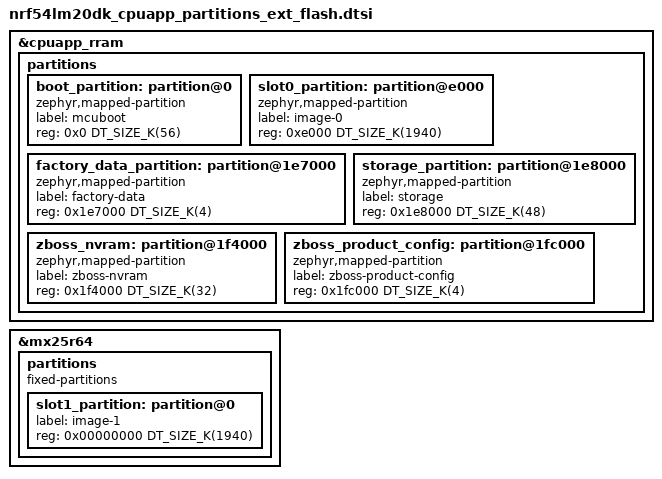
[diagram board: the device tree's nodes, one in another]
/*
 * Copyright (c) 2026 Nordic Semiconductor ASA
 *
 * SPDX-License-Identifier: LicenseRef-Nordic-5-Clause
 */

/delete-node/ &boot_partition;
/delete-node/ &slot0_partition;
/delete-node/ &slot1_partition;
/delete-node/ &storage_partition;
/delete-node/ &factory_data_partition;
/delete-node/ &zboss_nvram;
/delete-node/ &zboss_product_config;

&cpuapp_rram {
	partitions {
		boot_partition: partition@0 {
			compatible = "zephyr,mapped-partition";
			label = "mcuboot";
			reg = <0x0 DT_SIZE_K(56)>;
		};

		slot0_partition: partition@e000 {
			compatible = "zephyr,mapped-partition";
			label = "image-0";
			reg = <0xe000 DT_SIZE_K(1940)>;
		};

		factory_data_partition: partition@1e7000 {
			compatible = "zephyr,mapped-partition";
			label = "factory-data";
			reg = <0x1e7000 DT_SIZE_K(4)>;
		};

		storage_partition: partition@1e8000 {
			compatible = "zephyr,mapped-partition";
			label = "storage";
			reg = <0x1e8000 DT_SIZE_K(48)>;
		};

		zboss_nvram: partition@1f4000 {
			compatible = "zephyr,mapped-partition";
			label = "zboss-nvram";
			reg = <0x1f4000 DT_SIZE_K(32)>;
		};

		zboss_product_config: partition@1fc000 {
			compatible = "zephyr,mapped-partition";
			label = "zboss-product-config";
			reg = <0x1fc000 DT_SIZE_K(4)>;
		};
	};
};

&mx25r64 {
	status = "okay";

	partitions {
		compatible = "fixed-partitions";
		#address-cells = <1>;
		#size-cells = <1>;

		slot1_partition: partition@0 {
			label = "image-1";
			reg = <0x00000000 DT_SIZE_K(1940)>;
		};
	};
};
